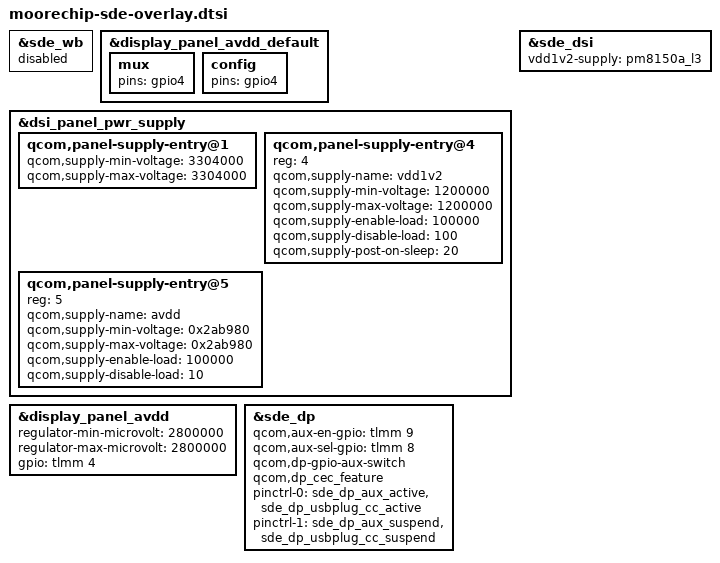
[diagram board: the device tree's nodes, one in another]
#include "dsi-panel-ch13726a-amoled-video.dtsi"

&sde_wb {
	status = "disabled";
};

&display_panel_avdd_default {
	mux {
		pins = "gpio4";
	};

	config {
		pins = "gpio4";
	};
};

&dsi_panel_pwr_supply {
	qcom,panel-supply-entry@1 {
		qcom,supply-min-voltage = <3304000>;
		qcom,supply-max-voltage = <3304000>;
	};

	qcom,panel-supply-entry@4 {
		reg = <4>;
		qcom,supply-name = "vdd1v2";
		qcom,supply-min-voltage = <1200000>;
		qcom,supply-max-voltage = <1200000>;
		qcom,supply-enable-load = <100000>;
		qcom,supply-disable-load = <100>;
		qcom,supply-post-on-sleep = <20>;
	};

	qcom,panel-supply-entry@5 {
		reg = <5>;
		qcom,supply-name = "avdd";
		qcom,supply-min-voltage = <0x2ab980>;
		qcom,supply-max-voltage = <0x2ab980>;
		qcom,supply-enable-load = <100000>;
		qcom,supply-disable-load = <10>;
	};
};

&display_panel_avdd {
	regulator-min-microvolt = <2800000>;
	regulator-max-microvolt = <2800000>;
	gpio = <&tlmm 4 0>;
};

&sde_dsi {
	/delete-property/ lab-supply;
	/delete-property/ ibb-supply;

	vdd1v2-supply = <&pm8150a_l3>;

	/delete-node/ ports;
};

&sde_dp {
	qcom,aux-en-gpio = <&tlmm 9 0>;
	qcom,aux-sel-gpio = <&tlmm 8 0>;
	qcom,dp-gpio-aux-switch;
	qcom,dp_cec_feature;

	pinctrl-0 = <&sde_dp_aux_active &sde_dp_usbplug_cc_active>;
	pinctrl-1 = <&sde_dp_aux_suspend &sde_dp_usbplug_cc_suspend>;
};

#if 0
// TODO: Can't overlay :(
&sde_dp {
	/delete-property/ qcom,dp-aux-switch;
};

&mdss_mdp {
	connectors = <&sde_dp &sde_dsi &sde_rscc>;
};
#endif
